AUTOSAR XML (schema 4-2-2)
package /Company/Components
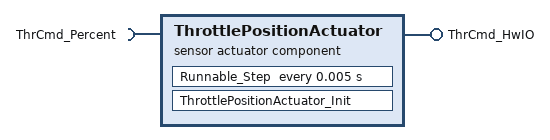
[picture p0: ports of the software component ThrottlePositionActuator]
  sensor actuator sw component type ThrottlePositionActuator
    require port ThrCmd_Percent: nonqueued-receiver-com-spec{data-element=Value, init-value=ComSpec3f1e8e08_48ae71bd53c3e72f:0}, required-interface=ThrCmd_Percent
    provide port ThrCmd_HwIO: nonqueued-sender-com-spec{data-element=Value, init-value=0}, provided-interface=ThrCmd_HwIO
    behavior ThrottlePositionActuator_InternalBehavior: data-type-mapping=ThrottlePositionActuatorDataTypeMappingsSet, handle-termination-and-restart=NO-SUPPORT
      timing event Event_Runnable_Step: start-on-event=Runnable_Step, period=0.005
      init event ThrottlePositionActuator_InitEvent: start-on-event=ThrottlePositionActuator_Init
      runnable Runnable_Step
        data-read-access:
          access IN_ThrCmd_Percent_Value: accessed-variable=ThrCmd_Percent.Value
        data-write-access:
          access OUT_ThrCmd_HwIO_Value: accessed-variable=ThrCmd_HwIO.Value
        parameter access SCALPRM_HBridgeCmd_LkupTbl: accessed-parameter=HBridgeCmd_LkupTbl, sw-calprm-axis-set={sw-axis-index=1, sw-axis-individual=sw-variable=ThrCmd_Percent.Value}
      runnable ThrottlePositionActuator_Init
      shared-parameters:
        parameter data prototype HBridgeCmd_LkupTbl: category=CURVE, sw-calibration-access=READ-WRITE, type=Appl_HBridgeCmd_LkupTbl, init-value=constant-reference={short-label=HBridgeCmd_LkupTbl, constant=HBridgeCmd_LkupTbl}
